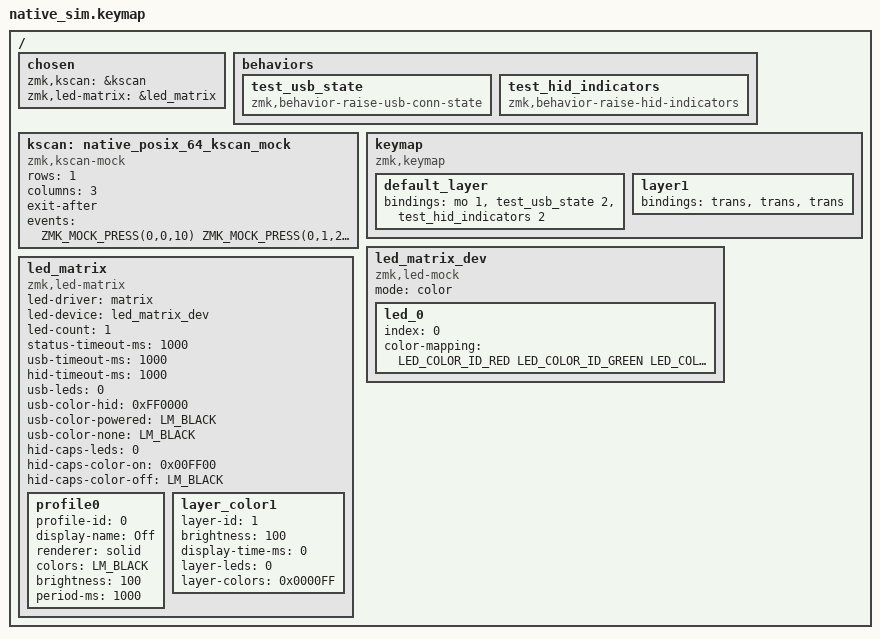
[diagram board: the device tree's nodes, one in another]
#include <dt-bindings/zmk/keys.h>
#include <dt-bindings/zmk/kscan_mock.h>
#include <dt-bindings/zmk/led_matrix.h>
#include <dt-bindings/zmk/led_matrix_colors.h>
#include <dt-bindings/led/led.h>
#include <behaviors.dtsi>

/ {
    chosen {
        zmk,kscan = &kscan;
        zmk,led-matrix = &led_matrix;
    };

    behaviors {
        test_usb_state: test_usb_state {
            compatible = "zmk,behavior-raise-usb-conn-state";
            #binding-cells = <1>;
        };

        test_hid_indicators: test_hid_indicators {
            compatible = "zmk,behavior-raise-hid-indicators";
            #binding-cells = <1>;
        };
    };

    kscan: native_posix_64_kscan_mock {
        compatible = "zmk,kscan-mock";
        rows = <1>;
        columns = <3>;
        exit-after;
        events = <
            ZMK_MOCK_PRESS(0,0,10)
            ZMK_MOCK_PRESS(0,1,20)
            ZMK_MOCK_RELEASE(0,1,10)
            ZMK_MOCK_PRESS(0,2,120)
            ZMK_MOCK_RELEASE(0,2,10)
            ZMK_MOCK_RELEASE(0,0,40)
        >;
    };

    keymap {
        compatible = "zmk,keymap";

        default_layer {
            bindings = <
                &mo 1 &test_usb_state 2 &test_hid_indicators 2
            >;
        };

        layer1 {
            bindings = <
                &trans &trans &trans
            >;
        };
    };

    led_matrix_dev: led_matrix_dev {
        compatible = "zmk,led-mock";
        mode = "color";

        led_0 { index = <0>; color-mapping = <LED_COLOR_ID_RED LED_COLOR_ID_GREEN LED_COLOR_ID_BLUE>; };
    };

    led_matrix: led_matrix {
        compatible = "zmk,led-matrix";
        led-driver = "matrix";
        led-device = <&led_matrix_dev>;
        led-count = <1>;
        status-timeout-ms = <1000>;
        usb-timeout-ms = <1000>;
        hid-timeout-ms = <1000>;
        usb-leds = <0>;
        usb-color-hid = <0xFF0000>;
        usb-color-powered = <LM_BLACK>;
        usb-color-none = <LM_BLACK>;
        hid-caps-leds = <0>;
        hid-caps-color-on = <0x00FF00>;
        hid-caps-color-off = <LM_BLACK>;

        profile0 {
            profile-id = <0>;
            display-name = "Off";
            renderer = "solid";
            colors = <LM_BLACK>;
            brightness = <100>;
            period-ms = <1000>;
        };

        layer_color1 {
            layer-id = <1>;
            brightness = <100>;
            display-time-ms = <0>;
            layer-leds = <0>;
            layer-colors = <0x0000FF>;
        };
    };
};
